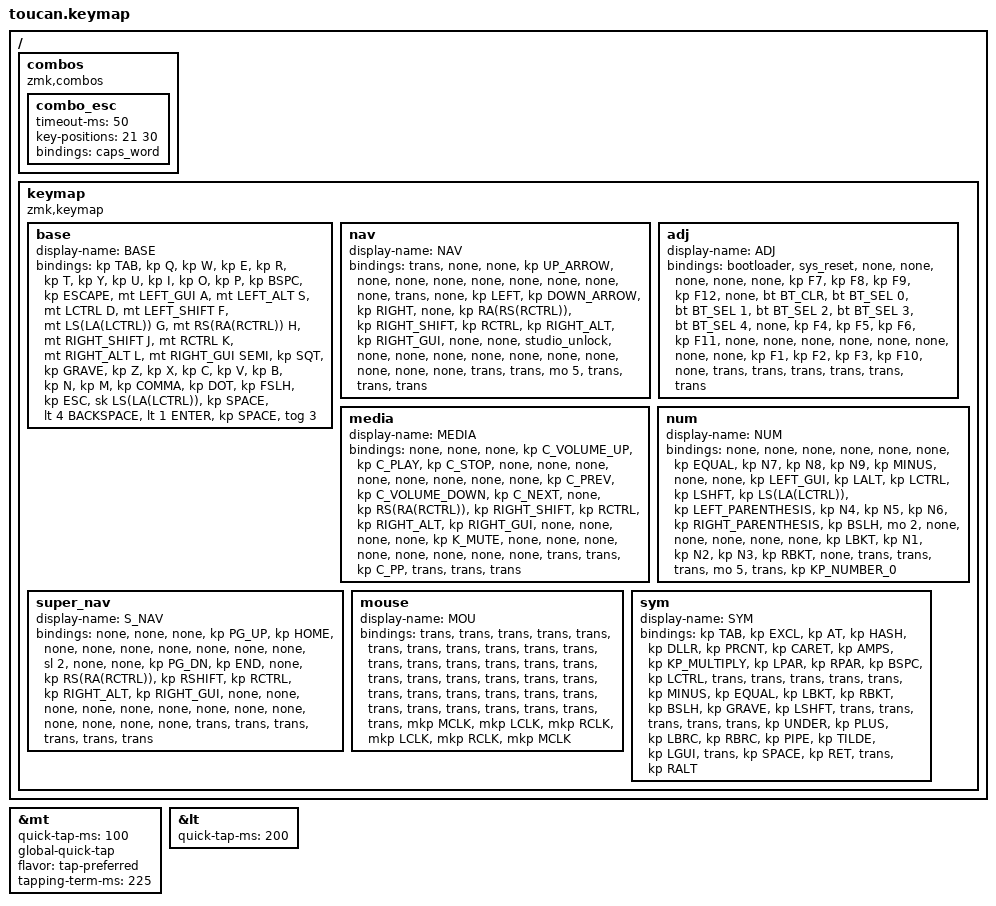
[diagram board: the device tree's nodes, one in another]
#include <behaviors.dtsi>
#include <dt-bindings/zmk/bt.h>
#include <dt-bindings/zmk/keys.h>
#include <dt-bindings/zmk/pointing.h>

#define BASE 0
#define NAV  1
#define ADJ  2
#define MEDIA 3
#define NUM 4
#define S_NAV 5
#define MOUSE 6
#define SYM 7

&mt {
    quick-tap-ms = <100>;
    global-quick-tap;
    flavor = "tap-preferred";
    tapping-term-ms = <225>;
};

&lt { quick-tap-ms = <200>; };

/ {
    combos {
        compatible = "zmk,combos";

        combo_esc {
            timeout-ms = <50>;
            key-positions = <21 30>;
            bindings = <&caps_word>;
        };
    };

    keymap {
        compatible = "zmk,keymap";

        base {
            display-name = "BASE";
            bindings = <
&kp TAB  &kp Q  &kp W  &kp E  &kp R  &kp T  &kp Y  &kp U  &kp I  &kp O  &kp P  &kp BSPC  &kp ESCAPE  &mt LEFT_GUI A  &mt LEFT_ALT S  &mt LCTRL D  &mt LEFT_SHIFT F  &mt LS(LA(LCTRL)) G  &mt RS(RA(RCTRL)) H  &mt RIGHT_SHIFT J  &mt RCTRL K  &mt RIGHT_ALT L  &mt RIGHT_GUI SEMI  &kp SQT  &kp GRAVE  &kp Z  &kp X  &kp C  &kp V  &kp B  &kp N  &kp M  &kp COMMA  &kp DOT  &kp FSLH  &kp ESC  &sk LS(LA(LCTRL))  &kp SPACE  &lt 4 BACKSPACE  &lt 1 ENTER  &kp SPACE  &tog 3
            >;
        };

        nav {
            display-name = "NAV";
            bindings = <
&trans  &none  &none  &kp UP_ARROW  &none  &none  &none  &none  &none  &none  &none  &none  &trans  &none  &kp LEFT  &kp DOWN_ARROW  &kp RIGHT  &none  &kp RA(RS(RCTRL))  &kp RIGHT_SHIFT  &kp RCTRL  &kp RIGHT_ALT  &kp RIGHT_GUI  &none  &none  &studio_unlock  &none  &none  &none  &none  &none  &none  &none  &none  &none  &none  &trans  &trans  &mo 5  &trans  &trans  &trans
            >;
        };

        adj {
            display-name = "ADJ";
            bindings = <
&bootloader  &sys_reset  &none  &none  &none  &none  &none  &kp F7  &kp F8  &kp F9  &kp F12  &none  &bt BT_CLR  &bt BT_SEL 0  &bt BT_SEL 1  &bt BT_SEL 2  &bt BT_SEL 3  &bt BT_SEL 4  &none  &kp F4  &kp F5  &kp F6  &kp F11  &none  &none  &none  &none  &none  &none  &none  &none  &kp F1  &kp F2  &kp F3  &kp F10  &none  &trans  &trans  &trans  &trans  &trans  &trans
            >;
        };

        media {
            display-name = "MEDIA";
            bindings = <
&none  &none  &none  &kp C_VOLUME_UP  &kp C_PLAY  &kp C_STOP  &none  &none  &none  &none  &none  &none  &none  &none  &kp C_PREV  &kp C_VOLUME_DOWN  &kp C_NEXT  &none  &kp RS(RA(RCTRL))  &kp RIGHT_SHIFT  &kp RCTRL  &kp RIGHT_ALT  &kp RIGHT_GUI  &none  &none  &none  &none  &kp K_MUTE  &none  &none  &none  &none  &none  &none  &none  &none  &trans  &trans  &kp C_PP  &trans  &trans  &trans
            >;
        };

        num {
            display-name = "NUM";
            bindings = <
&none  &none  &none  &none  &none  &none  &kp EQUAL  &kp N7  &kp N8  &kp N9  &kp MINUS  &none  &none  &kp LEFT_GUI  &kp LALT  &kp LCTRL  &kp LSHFT  &kp LS(LA(LCTRL))  &kp LEFT_PARENTHESIS  &kp N4  &kp N5  &kp N6  &kp RIGHT_PARENTHESIS  &kp BSLH  &mo 2  &none  &none  &none  &none  &none  &kp LBKT  &kp N1  &kp N2  &kp N3  &kp RBKT  &none  &trans  &trans  &trans  &mo 5  &trans  &kp KP_NUMBER_0
            >;
        };

        super_nav {
            display-name = "S_NAV";
            bindings = <
&none  &none  &none  &kp PG_UP  &kp HOME  &none  &none  &none  &none  &none  &none  &none  &sl 2  &none  &none  &kp PG_DN  &kp END  &none  &kp RS(RA(RCTRL))  &kp RSHIFT  &kp RCTRL  &kp RIGHT_ALT  &kp RIGHT_GUI  &none  &none  &none  &none  &none  &none  &none  &none  &none  &none  &none  &none  &none  &trans  &trans  &trans  &trans  &trans  &trans
            >;
        };

        mouse {
            display-name = "MOU";
            bindings = <
&trans  &trans  &trans  &trans  &trans  &trans  &trans  &trans  &trans  &trans  &trans  &trans  &trans  &trans  &trans  &trans  &trans  &trans  &trans  &trans  &trans  &trans  &trans  &trans  &trans  &trans  &trans  &trans  &trans  &trans  &trans  &trans  &trans  &trans  &trans  &trans  &mkp MCLK  &mkp LCLK  &mkp RCLK  &mkp LCLK  &mkp RCLK  &mkp MCLK
            >;
        };

        sym {
            display-name = "SYM";
            bindings = <
&kp TAB  &kp EXCL  &kp AT  &kp HASH  &kp DLLR  &kp PRCNT  &kp CARET  &kp AMPS  &kp KP_MULTIPLY  &kp LPAR  &kp RPAR  &kp BSPC  &kp LCTRL  &trans  &trans  &trans  &trans  &trans  &kp MINUS  &kp EQUAL  &kp LBKT  &kp RBKT  &kp BSLH  &kp GRAVE  &kp LSHFT  &trans  &trans  &trans  &trans  &trans  &kp UNDER  &kp PLUS  &kp LBRC  &kp RBRC  &kp PIPE  &kp TILDE  &kp LGUI  &trans  &kp SPACE  &kp RET  &trans  &kp RALT
            >;
        };
    };
};
